AUTOSAR XML (schema 4-3-0)
package /MICROSAR/Dem_swc/DataTypes
  19 x impl type:
    Dem_EventIdType: range raw 1..65535, implementation-data-type=uint16
    Dem_RatioIdType: range raw 1..65535, implementation-data-type=uint16
    Dem_DTCStatusMaskType: range raw 0..255, implementation-data-type=uint8
    Dem_OperationCycleIdType: range raw 0..255, implementation-data-type=uint8
    Dem_DTCGroupType: range raw 0..16777215, implementation-data-type=uint32
    Dem_MaxDataValueType: category=ARRAY, sw-calibration-access=READ-ONLY
      element Dem_MaxDataValueTypeElement: array-size=1, array-size-semantics=FIXED-SIZE, implementation-data-type=uint8
    Dem_EventStatusType: compu {0=DEM_EVENT_STATUS_PASSED, 1=DEM_EVENT_STATUS_FAILED, 2=DEM_EVENT_STATUS_PREPASSED, 3=DEM_EVENT_STATUS_PREFAILED}, implementation-data-type=uint8
    Dem_EventStatusExtendedType: compu {1=DEM_UDS_STATUS_TF, 2=DEM_UDS_STATUS_TFTOC, 4=DEM_UDS_STATUS_PDTC, 8=DEM_UDS_STATUS_CDTC, 16=DEM_UDS_STATUS_TNCSLC, 32=DEM_UDS_STATUS_TFSLC, 64=DEM_UDS_STATUS_TNCTOC, 128=DEM_UDS_STATUS_WIR}, implementation-data-type=uint8
    Dem_UdsStatusByteType: compu {1=DEM_UDS_STATUS_TF, 2=DEM_UDS_STATUS_TFTOC, 4=DEM_UDS_STATUS_PDTC, 8=DEM_UDS_STATUS_CDTC, 16=DEM_UDS_STATUS_TNCSLC, 32=DEM_UDS_STATUS_TFSLC, 64=DEM_UDS_STATUS_TNCTOC, 128=DEM_UDS_STATUS_WIR}, implementation-data-type=uint8
    Dem_InitMonitorReasonType: compu {1=DEM_INIT_MONITOR_CLEAR, 2=DEM_INIT_MONITOR_RESTART, 3=DEM_INIT_MONITOR_REENABLED, 4=DEM_INIT_MONITOR_STORAGE_REENABLED}, implementation-data-type=uint8
    Dem_DTCOriginType: compu {1=DEM_DTC_ORIGIN_PRIMARY_MEMORY, 2=DEM_DTC_ORIGIN_MIRROR_MEMORY, 3=DEM_DTC_ORIGIN_PERMANENT_MEMORY, 4=DEM_DTC_ORIGIN_SECONDARY_MEMORY, 4=DEM_DTC_ORIGIN_USERDEFINED_MEMORY_10, 4=DEM_DTC_ORIGIN_USERDEFINED_MEMORY_11, 4=DEM_DTC_ORIGIN_USERDEFINED_MEMORY_12, 4=DEM_DTC_ORIGIN_USERDEFINED_MEMORY_13, 4=DEM_DTC_ORIGIN_USERDEFINED_MEMORY_14, 4=DEM_DTC_ORIGIN_USERDEFINED_MEMORY_15, 4=DEM_DTC_ORIGIN_USERDEFINED_MEMORY_16, 4=DEM_DTC_ORIGIN_USERDEFINED_MEMORY_17, 4=DEM_DTC_ORIGIN_USERDEFINED_MEMORY_18, 4=DEM_DTC_ORIGIN_USERDEFINED_MEMORY_19, 4=DEM_DTC_ORIGIN_USERDEFINED_MEMORY_1A, 4=DEM_DTC_ORIGIN_USERDEFINED_MEMORY_1B, 4=DEM_DTC_ORIGIN_USERDEFINED_MEMORY_1C, 4=DEM_DTC_ORIGIN_USERDEFINED_MEMORY_1D, 4=DEM_DTC_ORIGIN_USERDEFINED_MEMORY_1E, 4=DEM_DTC_ORIGIN_USERDEFINED_MEMORY_1F, 4=DEM_DTC_ORIGIN_USERDEFINED_MEMORY_20, 4=DEM_DTC_ORIGIN_USERDEFINED_MEMORY_21, 4=DEM_DTC_ORIGIN_USERDEFINED_MEMORY_22, 4=DEM_DTC_ORIGIN_USERDEFINED_MEMORY_23, 4=DEM_DTC_ORIGIN_USERDEFINED_MEMORY_24, 4=DEM_DTC_ORIGIN_USERDEFINED_MEMORY_25, 4=DEM_DTC_ORIGIN_USERDEFINED_MEMORY_26, 4=DEM_DTC_ORIGIN_USERDEFINED_MEMORY_27, 4=DEM_DTC_ORIGIN_USERDEFINED_MEMORY_28, 4=DEM_DTC_ORIGIN_USERDEFINED_MEMORY_29, 4=DEM_DTC_ORIGIN_USERDEFINED_MEMORY_2A, 4=DEM_DTC_ORIGIN_USERDEFINED_MEMORY_2B, 4=DEM_DTC_ORIGIN_USERDEFINED_MEMORY_2C, 4=DEM_DTC_ORIGIN_USERDEFINED_MEMORY_2D, 4=DEM_DTC_ORIGIN_USERDEFINED_MEMORY_2E, 4=DEM_DTC_ORIGIN_USERDEFINED_MEMORY_2F, 4=DEM_DTC_ORIGIN_USERDEFINED_MEMORY_30, 4=DEM_DTC_ORIGIN_USERDEFINED_MEMORY_31, 4=DEM_DTC_ORIGIN_USERDEFINED_MEMORY_32, 4=DEM_DTC_ORIGIN_USERDEFINED_MEMORY_33, 4=DEM_DTC_ORIGIN_USERDEFINED_MEMORY_34, 4=DEM_DTC_ORIGIN_USERDEFINED_MEMORY_35, 4=DEM_DTC_ORIGIN_USERDEFINED_MEMORY_36, 4=DEM_DTC_ORIGIN_USERDEFINED_MEMORY_37, 4=DEM_DTC_ORIGIN_USERDEFINED_MEMORY_38, 4=DEM_DTC_ORIGIN_USERDEFINED_MEMORY_39, 4=DEM_DTC_ORIGIN_USERDEFINED_MEMORY_3A, 4=DEM_DTC_ORIGIN_USERDEFINED_MEMORY_3B, 4=DEM_DTC_ORIGIN_USERDEFINED_MEMORY_3C, 4=DEM_DTC_ORIGIN_USERDEFINED_MEMORY_3D, 4=DEM_DTC_ORIGIN_USERDEFINED_MEMORY_3E, 4=DEM_DTC_ORIGIN_USERDEFINED_MEMORY_3F, 4=DEM_DTC_ORIGIN_USERDEFINED_MEMORY_40, 4=DEM_DTC_ORIGIN_USERDEFINED_MEMORY_41, 4=DEM_DTC_ORIGIN_USERDEFINED_MEMORY_42, 4=DEM_DTC_ORIGIN_USERDEFINED_MEMORY_43, 4=DEM_DTC_ORIGIN_USERDEFINED_MEMORY_44, 4=DEM_DTC_ORIGIN_USERDEFINED_MEMORY_45, 4=DEM_DTC_ORIGIN_USERDEFINED_MEMORY_46, 4=DEM_DTC_ORIGIN_USERDEFINED_MEMORY_47, 4=DEM_DTC_ORIGIN_USERDEFINED_MEMORY_48, 4=DEM_DTC_ORIGIN_USERDEFINED_MEMORY_49, 4=DEM_DTC_ORIGIN_USERDEFINED_MEMORY_4A, 4=DEM_DTC_ORIGIN_USERDEFINED_MEMORY_4B, 4=DEM_DTC_ORIGIN_USERDEFINED_MEMORY_4C, 4=DEM_DTC_ORIGIN_USERDEFINED_MEMORY_4D, 4=DEM_DTC_ORIGIN_USERDEFINED_MEMORY_4E, 4=DEM_DTC_ORIGIN_USERDEFINED_MEMORY_4F, 4=DEM_DTC_ORIGIN_USERDEFINED_MEMORY_50, 4=DEM_DTC_ORIGIN_USERDEFINED_MEMORY_51, 4=DEM_DTC_ORIGIN_USERDEFINED_MEMORY_52, 4=DEM_DTC_ORIGIN_USERDEFINED_MEMORY_53, 4=DEM_DTC_ORIGIN_USERDEFINED_MEMORY_54, 4=DEM_DTC_ORIGIN_USERDEFINED_MEMORY_55, 4=DEM_DTC_ORIGIN_USERDEFINED_MEMORY_56, 4=DEM_DTC_ORIGIN_USERDEFINED_MEMORY_57, 4=DEM_DTC_ORIGIN_USERDEFINED_MEMORY_58, 4=DEM_DTC_ORIGIN_USERDEFINED_MEMORY_59, 4=DEM_DTC_ORIGIN_USERDEFINED_MEMORY_5A, 4=DEM_DTC_ORIGIN_USERDEFINED_MEMORY_5B, 4=DEM_DTC_ORIGIN_USERDEFINED_MEMORY_5C, 4=DEM_DTC_ORIGIN_USERDEFINED_MEMORY_5D, 4=DEM_DTC_ORIGIN_USERDEFINED_MEMORY_5E, 4=DEM_DTC_ORIGIN_USERDEFINED_MEMORY_5F, 4=DEM_DTC_ORIGIN_USERDEFINED_MEMORY_60, 4=DEM_DTC_ORIGIN_USERDEFINED_MEMORY_61, 4=DEM_DTC_ORIGIN_USERDEFINED_MEMORY_62, 4=DEM_DTC_ORIGIN_USERDEFINED_MEMORY_63, 4=DEM_DTC_ORIGIN_USERDEFINED_MEMORY_64, 4=DEM_DTC_ORIGIN_USERDEFINED_MEMORY_65, 4=DEM_DTC_ORIGIN_USERDEFINED_MEMORY_66, 4=DEM_DTC_ORIGIN_USERDEFINED_MEMORY_67, 4=DEM_DTC_ORIGIN_USERDEFINED_MEMORY_68, 4=DEM_DTC_ORIGIN_USERDEFINED_MEMORY_69, 4=DEM_DTC_ORIGIN_USERDEFINED_MEMORY_6A, 4=DEM_DTC_ORIGIN_USERDEFINED_MEMORY_6B, 4=DEM_DTC_ORIGIN_USERDEFINED_MEMORY_6C, 4=DEM_DTC_ORIGIN_USERDEFINED_MEMORY_6D, 4=DEM_DTC_ORIGIN_USERDEFINED_MEMORY_6E, 4=DEM_DTC_ORIGIN_USERDEFINED_MEMORY_6F, 4=DEM_DTC_ORIGIN_USERDEFINED_MEMORY_70, 4=DEM_DTC_ORIGIN_USERDEFINED_MEMORY_71, 4=DEM_DTC_ORIGIN_USERDEFINED_MEMORY_72, 4=DEM_DTC_ORIGIN_USERDEFINED_MEMORY_73, 4=DEM_DTC_ORIGIN_USERDEFINED_MEMORY_74, 4=DEM_DTC_ORIGIN_USERDEFINED_MEMORY_75, 4=DEM_DTC_ORIGIN_USERDEFINED_MEMORY_76, 4=DEM_DTC_ORIGIN_USERDEFINED_MEMORY_77, 4=DEM_DTC_ORIGIN_USERDEFINED_MEMORY_78, 4=DEM_DTC_ORIGIN_USERDEFINED_MEMORY_79, 4=DEM_DTC_ORIGIN_USERDEFINED_MEMORY_7A, 4=DEM_DTC_ORIGIN_USERDEFINED_MEMORY_7B, 4=DEM_DTC_ORIGIN_USERDEFINED_MEMORY_7C, 4=DEM_DTC_ORIGIN_USERDEFINED_MEMORY_7D, 4=DEM_DTC_ORIGIN_USERDEFINED_MEMORY_7E, 4=DEM_DTC_ORIGIN_USERDEFINED_MEMORY_7F, 4=DEM_DTC_ORIGIN_USERDEFINED_MEMORY_80, 4=DEM_DTC_ORIGIN_USERDEFINED_MEMORY_81, 4=DEM_DTC_ORIGIN_USERDEFINED_MEMORY_82, 4=DEM_DTC_ORIGIN_USERDEFINED_MEMORY_83, 4=DEM_DTC_ORIGIN_USERDEFINED_MEMORY_84, 4=DEM_DTC_ORIGIN_USERDEFINED_MEMORY_85, 4=DEM_DTC_ORIGIN_USERDEFINED_MEMORY_86, 4=DEM_DTC_ORIGIN_USERDEFINED_MEMORY_87, 4=DEM_DTC_ORIGIN_USERDEFINED_MEMORY_88, 4=DEM_DTC_ORIGIN_USERDEFINED_MEMORY_89, 4=DEM_DTC_ORIGIN_USERDEFINED_MEMORY_8A, 4=DEM_DTC_ORIGIN_USERDEFINED_MEMORY_8B, 4=DEM_DTC_ORIGIN_USERDEFINED_MEMORY_8C, 4=DEM_DTC_ORIGIN_USERDEFINED_MEMORY_8D, 4=DEM_DTC_ORIGIN_USERDEFINED_MEMORY_8E, 4=DEM_DTC_ORIGIN_USERDEFINED_MEMORY_8F, 4=DEM_DTC_ORIGIN_USERDEFINED_MEMORY_90, 4=DEM_DTC_ORIGIN_USERDEFINED_MEMORY_91, 4=DEM_DTC_ORIGIN_USERDEFINED_MEMORY_92, 4=DEM_DTC_ORIGIN_USERDEFINED_MEMORY_93, 4=DEM_DTC_ORIGIN_USERDEFINED_MEMORY_94, 4=DEM_DTC_ORIGIN_USERDEFINED_MEMORY_95, 4=DEM_DTC_ORIGIN_USERDEFINED_MEMORY_96, 4=DEM_DTC_ORIGIN_USERDEFINED_MEMORY_97, 4=DEM_DTC_ORIGIN_USERDEFINED_MEMORY_98, 4=DEM_DTC_ORIGIN_USERDEFINED_MEMORY_99, 4=DEM_DTC_ORIGIN_USERDEFINED_MEMORY_9A, 4=DEM_DTC_ORIGIN_USERDEFINED_MEMORY_9B, 4=DEM_DTC_ORIGIN_USERDEFINED_MEMORY_9C, 4=DEM_DTC_ORIGIN_USERDEFINED_MEMORY_9D, 4=DEM_DTC_ORIGIN_USERDEFINED_MEMORY_9E, 4=DEM_DTC_ORIGIN_USERDEFINED_MEMORY_9F, 4=DEM_DTC_ORIGIN_USERDEFINED_MEMORY_A0, 4=DEM_DTC_ORIGIN_USERDEFINED_MEMORY_A1, 4=DEM_DTC_ORIGIN_USERDEFINED_MEMORY_A2, 4=DEM_DTC_ORIGIN_USERDEFINED_MEMORY_A3, 4=DEM_DTC_ORIGIN_USERDEFINED_MEMORY_A4, 4=DEM_DTC_ORIGIN_USERDEFINED_MEMORY_A5, 4=DEM_DTC_ORIGIN_USERDEFINED_MEMORY_A6, 4=DEM_DTC_ORIGIN_USERDEFINED_MEMORY_A7, 4=DEM_DTC_ORIGIN_USERDEFINED_MEMORY_A8, 4=DEM_DTC_ORIGIN_USERDEFINED_MEMORY_A9, 4=DEM_DTC_ORIGIN_USERDEFINED_MEMORY_AA, 4=DEM_DTC_ORIGIN_USERDEFINED_MEMORY_AB, 4=DEM_DTC_ORIGIN_USERDEFINED_MEMORY_AC, 4=DEM_DTC_ORIGIN_USERDEFINED_MEMORY_AD, 4=DEM_DTC_ORIGIN_USERDEFINED_MEMORY_AE, 4=DEM_DTC_ORIGIN_USERDEFINED_MEMORY_AF, 4=DEM_DTC_ORIGIN_USERDEFINED_MEMORY_B0, 4=DEM_DTC_ORIGIN_USERDEFINED_MEMORY_B1, 4=DEM_DTC_ORIGIN_USERDEFINED_MEMORY_B2, 4=DEM_DTC_ORIGIN_USERDEFINED_MEMORY_B3, 4=DEM_DTC_ORIGIN_USERDEFINED_MEMORY_B4, 4=DEM_DTC_ORIGIN_USERDEFINED_MEMORY_B5, 4=DEM_DTC_ORIGIN_USERDEFINED_MEMORY_B6, 4=DEM_DTC_ORIGIN_USERDEFINED_MEMORY_B7, 4=DEM_DTC_ORIGIN_USERDEFINED_MEMORY_B8, 4=DEM_DTC_ORIGIN_USERDEFINED_MEMORY_B9, 4=DEM_DTC_ORIGIN_USERDEFINED_MEMORY_BA, 4=DEM_DTC_ORIGIN_USERDEFINED_MEMORY_BB, 4=DEM_DTC_ORIGIN_USERDEFINED_MEMORY_BC, 4=DEM_DTC_ORIGIN_USERDEFINED_MEMORY_BD, 4=DEM_DTC_ORIGIN_USERDEFINED_MEMORY_BE, 4=DEM_DTC_ORIGIN_USERDEFINED_MEMORY_BF, 4=DEM_DTC_ORIGIN_USERDEFINED_MEMORY_C0, 4=DEM_DTC_ORIGIN_USERDEFINED_MEMORY_C1, 4=DEM_DTC_ORIGIN_USERDEFINED_MEMORY_C2, 4=DEM_DTC_ORIGIN_USERDEFINED_MEMORY_C3, 4=DEM_DTC_ORIGIN_USERDEFINED_MEMORY_C4, 4=DEM_DTC_ORIGIN_USERDEFINED_MEMORY_C5, 4=DEM_DTC_ORIGIN_USERDEFINED_MEMORY_C6, 4=DEM_DTC_ORIGIN_USERDEFINED_MEMORY_C7, 4=DEM_DTC_ORIGIN_USERDEFINED_MEMORY_C8, 4=DEM_DTC_ORIGIN_USERDEFINED_MEMORY_C9, 4=DEM_DTC_ORIGIN_USERDEFINED_MEMORY_CA, 4=DEM_DTC_ORIGIN_USERDEFINED_MEMORY_CB, 4=DEM_DTC_ORIGIN_USERDEFINED_MEMORY_CC, 4=DEM_DTC_ORIGIN_USERDEFINED_MEMORY_CD, 4=DEM_DTC_ORIGIN_USERDEFINED_MEMORY_CE, 4=DEM_DTC_ORIGIN_USERDEFINED_MEMORY_CF, 4=DEM_DTC_ORIGIN_USERDEFINED_MEMORY_D0, 4=DEM_DTC_ORIGIN_USERDEFINED_MEMORY_D1, 4=DEM_DTC_ORIGIN_USERDEFINED_MEMORY_D2, 4=DEM_DTC_ORIGIN_USERDEFINED_MEMORY_D3, 4=DEM_DTC_ORIGIN_USERDEFINED_MEMORY_D4, 4=DEM_DTC_ORIGIN_USERDEFINED_MEMORY_D5, 4=DEM_DTC_ORIGIN_USERDEFINED_MEMORY_D6, 4=DEM_DTC_ORIGIN_USERDEFINED_MEMORY_D7, 4=DEM_DTC_ORIGIN_USERDEFINED_MEMORY_D8, 4=DEM_DTC_ORIGIN_USERDEFINED_MEMORY_D9, 4=DEM_DTC_ORIGIN_USERDEFINED_MEMORY_DA, 4=DEM_DTC_ORIGIN_USERDEFINED_MEMORY_DB, 4=DEM_DTC_ORIGIN_USERDEFINED_MEMORY_DC, 4=DEM_DTC_ORIGIN_USERDEFINED_MEMORY_DD, 4=DEM_DTC_ORIGIN_USERDEFINED_MEMORY_DE, 4=DEM_DTC_ORIGIN_USERDEFINED_MEMORY_DF, 4=DEM_DTC_ORIGIN_USERDEFINED_MEMORY_E0, 4=DEM_DTC_ORIGIN_USERDEFINED_MEMORY_E1, 4=DEM_DTC_ORIGIN_USERDEFINED_MEMORY_E2, 4=DEM_DTC_ORIGIN_USERDEFINED_MEMORY_E3, 4=DEM_DTC_ORIGIN_USERDEFINED_MEMORY_E4, 4=DEM_DTC_ORIGIN_USERDEFINED_MEMORY_E5, 4=DEM_DTC_ORIGIN_USERDEFINED_MEMORY_E6, 4=DEM_DTC_ORIGIN_USERDEFINED_MEMORY_E7, 4=DEM_DTC_ORIGIN_USERDEFINED_MEMORY_E8, 4=DEM_DTC_ORIGIN_USERDEFINED_MEMORY_E9, 4=DEM_DTC_ORIGIN_USERDEFINED_MEMORY_EA, 4=DEM_DTC_ORIGIN_USERDEFINED_MEMORY_EB, 4=DEM_DTC_ORIGIN_USERDEFINED_MEMORY_EC, 4=DEM_DTC_ORIGIN_USERDEFINED_MEMORY_ED, 4=DEM_DTC_ORIGIN_USERDEFINED_MEMORY_EE, 4=DEM_DTC_ORIGIN_USERDEFINED_MEMORY_EF, 4=DEM_DTC_ORIGIN_USERDEFINED_MEMORY_F0, 4=DEM_DTC_ORIGIN_USERDEFINED_MEMORY_F1, 4=DEM_DTC_ORIGIN_USERDEFINED_MEMORY_F2, 4=DEM_DTC_ORIGIN_USERDEFINED_MEMORY_F3, 4=DEM_DTC_ORIGIN_USERDEFINED_MEMORY_F4, 4=DEM_DTC_ORIGIN_USERDEFINED_MEMORY_F5, 4=DEM_DTC_ORIGIN_USERDEFINED_MEMORY_F6, 4=DEM_DTC_ORIGIN_USERDEFINED_MEMORY_F7, 4=DEM_DTC_ORIGIN_USERDEFINED_MEMORY_F8, 4=DEM_DTC_ORIGIN_USERDEFINED_MEMORY_F9, 4=DEM_DTC_ORIGIN_USERDEFINED_MEMORY_FA, 4=DEM_DTC_ORIGIN_USERDEFINED_MEMORY_FB, 4=DEM_DTC_ORIGIN_USERDEFINED_MEMORY_FC, 4=DEM_DTC_ORIGIN_USERDEFINED_MEMORY_FD, 4=DEM_DTC_ORIGIN_USERDEFINED_MEMORY_FE, 4=DEM_DTC_ORIGIN_USERDEFINED_MEMORY_FF}, implementation-data-type=uint8
    Dem_DTCFormatType: compu {0=DEM_DTC_FORMAT_OBD, 1=DEM_DTC_FORMAT_UDS, 2=DEM_DTC_FORMAT_J1939}, implementation-data-type=uint8
    Dem_OperationCycleStateType: compu {0=DEM_CYCLE_STATE_START, 1=DEM_CYCLE_STATE_END}, implementation-data-type=uint8
    Dem_IndicatorStatusType: compu {0=DEM_INDICATOR_OFF, 1=DEM_INDICATOR_CONTINUOUS, 2=DEM_INDICATOR_BLINKING, 3=DEM_INDICATOR_BLINK_CONT, 4=DEM_INDICATOR_SLOW_FLASH, 5=DEM_INDICATOR_FAST_FLASH, 6=DEM_INDICATOR_ON_DEMAND, 7=DEM_INDICATOR_SHORT}, implementation-data-type=uint8
    Dem_DTCKindType: compu {1=DEM_DTC_KIND_ALL_DTCS, 2=DEM_DTC_KIND_EMISSION_REL_DTCS}, implementation-data-type=uint8
    Dem_IumprDenomCondIdType: compu {1=DEM_IUMPR_GENERAL_DENOMINATOR, 2=DEM_IUMPR_DEN_COND_COLDSTART, 3=DEM_IUMPR_DEN_COND_EVAP, 4=DEM_IUMPR_DEN_COND_500MI}, implementation-data-type=uint8
    Dem_IumprDenomCondStatusType: compu {0=DEM_IUMPR_DEN_STATUS_NOT_REACHED, 1=DEM_IUMPR_DEN_STATUS_REACHED, 2=DEM_IUMPR_DEN_STATUS_INHIBITED}, implementation-data-type=uint8
    Dem_DebounceResetStatusType: compu {0=DEM_DEBOUNCE_STATUS_FREEZE, 1=DEM_DEBOUNCE_STATUS_RESET}, implementation-data-type=uint8
    Dem_DebouncingStateType: compu {1=DEM_TEMPORARILY_DEFECTIVE, 2=DEM_FINALLY_DEFECTIVE, 4=DEM_TEMPORARILY_HEALED, 8=DEM_TEST_COMPLETE, 16=DEM_DTR_UPDATE}, implementation-data-type=uint8
package /MICROSAR/Dem_swc/Interfaces
  7 x client server interface, all with is-service=true, service-kind=DIAGNOSTIC-EVENT-MANAGER:
    CddIf
      operation ClearDTC: possible-error=[CddIf/DEM_CLEAR_WRONG_DTC, CddIf/DEM_CLEAR_WRONG_DTCORIGIN, CddIf/DEM_CLEAR_FAILED, CddIf/DEM_CLEAR_PENDING, CddIf/DEM_CLEAR_BUSY, CddIf/DEM_CLEAR_MEMORY_ERROR]
        arg DTC: type=uint32, direction=IN
        arg DTCFormat: type=Dem_DTCFormatType, direction=IN
        arg DTCOrigin: type=Dem_DTCOriginType, direction=IN
      6 x error:
        DEM_CLEAR_WRONG_DTC: error-code=1
        DEM_CLEAR_WRONG_DTCORIGIN: error-code=2
        DEM_CLEAR_FAILED: error-code=3
        DEM_CLEAR_PENDING: error-code=4
        DEM_CLEAR_BUSY: error-code=5
        DEM_CLEAR_MEMORY_ERROR: error-code=6
    DemServices
      operation GetPostRunRequested: possible-error=DemServices/E_NOT_OK
        arg IsRequested: type=boolean, direction=OUT
      operation GetDTCStatusAvailabilityMask: possible-error=DemServices/E_NOT_OK
        arg DTCStatusMask: type=uint8, direction=OUT
      error E_NOT_OK: error-code=1
    EvMemOverflowIndication
      operation GetEventMemoryOverflow: possible-error=EvMemOverflowIndication/E_NOT_OK
        arg OverflowIndication: type=boolean, direction=OUT
      operation GetNumberOfEventMemoryEntries: possible-error=EvMemOverflowIndication/E_NOT_OK
        arg NumberOfEventMemoryEntries: type=uint8, direction=OUT
      error E_NOT_OK: error-code=1
    GeneralDiagnosticInfo
      9 x operation:
        GetEventStatus: possible-error=GeneralDiagnosticInfo/E_NOT_OK
          arg EventId: type=Dem_EventIdType, direction=IN
          arg EventStatusExtended: type=Dem_EventStatusExtendedType, direction=OUT
        GetEventFailed: possible-error=GeneralDiagnosticInfo/E_NOT_OK
          arg EventId: type=Dem_EventIdType, direction=IN
          arg EventFailed: type=boolean, direction=OUT
        GetEventTested: possible-error=GeneralDiagnosticInfo/E_NOT_OK
          arg EventId: type=Dem_EventIdType, direction=IN
          arg EventTested: type=boolean, direction=OUT
        GetDTCOfEvent: possible-error=[GeneralDiagnosticInfo/E_NOT_OK, GeneralDiagnosticInfo/DEM_E_NO_DTC_AVAILABLE]
          arg EventId: type=Dem_EventIdType, direction=IN
          arg DTCFormat: type=Dem_DTCFormatType, direction=IN
          arg DTCOfEvent: type=uint32, direction=OUT
        GetFaultDetectionCounter: possible-error=[GeneralDiagnosticInfo/E_NOT_OK, GeneralDiagnosticInfo/DEM_E_NO_FDC_AVAILABLE]
          arg EventId: type=Dem_EventIdType, direction=IN
          arg FaultDetectionCounter: type=sint8, direction=OUT
        GetEventFreezeFrameData: possible-error=[GeneralDiagnosticInfo/E_NOT_OK, GeneralDiagnosticInfo/DEM_E_NODATAAVAILABLE, GeneralDiagnosticInfo/DEM_E_WRONG_RECORDNUMBER, GeneralDiagnosticInfo/DEM_E_WRONG_DIDNUMBER]
          5 x arg:
            EventId: type=Dem_EventIdType, direction=IN
            RecordNumber: type=uint8, direction=IN
            ReportTotalRecord: type=boolean, direction=IN
            DataId: type=uint16, direction=IN
            DestBuffer: type=Dem_MaxDataValueType, direction=OUT
        GetEventExtendedDataRecord: possible-error=[GeneralDiagnosticInfo/E_NOT_OK, GeneralDiagnosticInfo/DEM_E_NODATAAVAILABLE, GeneralDiagnosticInfo/DEM_E_WRONG_RECORDNUMBER]
          arg EventId: type=Dem_EventIdType, direction=IN
          arg RecordNumber: type=uint8, direction=IN
          arg DestBuffer: type=Dem_MaxDataValueType, direction=OUT
        GetEventEnableCondition: possible-error=GeneralDiagnosticInfo/E_NOT_OK
          arg EventId: type=Dem_EventIdType, direction=IN
          arg ConditionFullfilled: type=boolean, direction=OUT
        GetDebouncingOfEvent: possible-error=GeneralDiagnosticInfo/E_NOT_OK
          arg EventId: type=Dem_EventIdType, direction=IN
          arg DebouncingState: type=Dem_DebouncingStateType, direction=OUT
      6 x error:
        E_NOT_OK: error-code=1
        DEM_E_NO_DTC_AVAILABLE: error-code=2
        DEM_E_NO_FDC_AVAILABLE: error-code=3
        DEM_E_NODATAAVAILABLE: error-code=48
        DEM_E_WRONG_RECORDNUMBER: error-code=49
        DEM_E_WRONG_DIDNUMBER: error-code=50
    DiagnosticInfo
      9 x operation:
        GetEventStatus: possible-error=DiagnosticInfo/E_NOT_OK
          arg EventStatusExtended: type=Dem_EventStatusExtendedType, direction=OUT
        GetEventFailed: possible-error=DiagnosticInfo/E_NOT_OK
          arg EventFailed: type=boolean, direction=OUT
        GetEventTested: possible-error=DiagnosticInfo/E_NOT_OK
          arg EventTested: type=boolean, direction=OUT
        GetDTCOfEvent: possible-error=[DiagnosticInfo/E_NOT_OK, DiagnosticInfo/DEM_E_NO_DTC_AVAILABLE]
          arg DTCFormat: type=Dem_DTCFormatType, direction=IN
          arg DTCOfEvent: type=uint32, direction=OUT
        GetFaultDetectionCounter: possible-error=[DiagnosticInfo/E_NOT_OK, DiagnosticInfo/DEM_E_NO_FDC_AVAILABLE]
          arg FaultDetectionCounter: type=sint8, direction=OUT
        GetEventFreezeFrameData: possible-error=[DiagnosticInfo/E_NOT_OK, DiagnosticInfo/DEM_E_NODATAAVAILABLE, DiagnosticInfo/DEM_E_WRONG_RECORDNUMBER, DiagnosticInfo/DEM_E_WRONG_DIDNUMBER]
          4 x arg:
            RecordNumber: type=uint8, direction=IN
            ReportTotalRecord: type=boolean, direction=IN
            DataId: type=uint16, direction=IN
            DestBuffer: type=Dem_MaxDataValueType, direction=OUT
        GetEventExtendedDataRecord: possible-error=[DiagnosticInfo/E_NOT_OK, DiagnosticInfo/DEM_E_NODATAAVAILABLE, DiagnosticInfo/DEM_E_WRONG_RECORDNUMBER]
          arg RecordNumber: type=uint8, direction=IN
          arg DestBuffer: type=Dem_MaxDataValueType, direction=OUT
        GetEventEnableCondition: possible-error=DiagnosticInfo/E_NOT_OK
          arg ConditionFullfilled: type=boolean, direction=OUT
        GetDebouncingOfEvent: possible-error=DiagnosticInfo/E_NOT_OK
          arg DebouncingState: type=Dem_DebouncingStateType, direction=OUT
      6 x error:
        E_NOT_OK: error-code=1
        DEM_E_NO_DTC_AVAILABLE: error-code=2
        DEM_E_NO_FDC_AVAILABLE: error-code=3
        DEM_E_NODATAAVAILABLE: error-code=48
        DEM_E_WRONG_RECORDNUMBER: error-code=49
        DEM_E_WRONG_DIDNUMBER: error-code=50
    DcmIf
      5 x operation:
        DcmClearDTC: possible-error=[DcmIf/DEM_CLEAR_WRONG_DTC, DcmIf/DEM_CLEAR_WRONG_DTCORIGIN, DcmIf/DEM_CLEAR_FAILED, DcmIf/DEM_CLEAR_PENDING, DcmIf/DEM_CLEAR_BUSY, DcmIf/DEM_CLEAR_MEMORY_ERROR]
          arg DTC: type=uint32, direction=IN
          arg DTCFormat: type=Dem_DTCFormatType, direction=IN
          arg DTCOrigin: type=Dem_DTCOriginType, direction=IN
        DcmGetNextFilteredDTCAndFDC: possible-error=DEM_FILTERED_NO_MATCHING_DTC
          arg DTC: type=uint32, direction=OUT
          arg DTCFaultDetectionCounter: type=sint8, direction=OUT
        DcmEnableDTCSetting: possible-error=[DEM_CONTROL_DTC_SETTING_N_OK, DEM_CONTROL_DTC_WRONG_DTCGROUP]
          arg DTCGroup: type=Dem_DTCGroupType, direction=IN
          arg DTCKind: type=Dem_DTCKindType, direction=IN
        DcmGetFreezeFrameDataByDTC: possible-error=[DEM_GET_FFDATABYDTC_WRONG_DTC, DEM_GET_FFDATABYDTC_WRONG_DTCORIGIN, DEM_GET_FFDATABYDTC_WRONG_RECORDNUMBER, DEM_GET_FFDATABYDTC_WRONG_BUFFERSIZE, DEM_GET_FFDATABYDTC_PENDING]
          5 x arg:
            DTC: type=uint32, direction=IN
            DTCOrigin: type=Dem_DTCOriginType, direction=IN
            RecordNumber: type=uint8, direction=IN
            DestBuffer: type=uint8, direction=OUT
            BufSize: type=uint16, direction=INOUT
        DcmGetExtendedDataRecordByDTC: possible-error=[DEM_RECORD_WRONG_DTC, DEM_RECORD_WRONG_DTCORIGIN, DEM_RECORD_WRONG_NUMBER, DEM_RECORD_WRONG_BUFFERSIZE, DEM_RECORD_PENDING]
          5 x arg:
            DTC: type=uint32, direction=IN
            DTCOrigin: type=Dem_DTCOriginType, direction=IN
            ExtendedDataNumber: type=uint8, direction=IN
            DestBuffer: type=uint8, direction=OUT
            BufSize: type=uint16, direction=INOUT
      19 x error:
        DEM_CLEAR_WRONG_DTC: error-code=1
        DEM_CONTROL_DTC_SETTING_N_OK: error-code=1
        DEM_FILTERED_NO_MATCHING_DTC: error-code=1
        DEM_GET_FFDATABYDTC_WRONG_DTC: error-code=1
        DEM_RECORD_WRONG_DTC: error-code=1
        DEM_CLEAR_WRONG_DTCORIGIN: error-code=2
        DEM_CONTROL_DTC_WRONG_DTCGROUP: error-code=2
        DEM_GET_FFDATABYDTC_WRONG_DTCORIGIN: error-code=2
        DEM_RECORD_WRONG_DTCORIGIN: error-code=2
        DEM_CLEAR_FAILED: error-code=3
        DEM_GET_FFDATABYDTC_WRONG_RECORDNUMBER: error-code=3
        DEM_RECORD_WRONG_NUMBER: error-code=3
        DEM_CLEAR_PENDING: error-code=4
        DEM_GET_FFDATABYDTC_WRONG_BUFFERSIZE: error-code=4
        DEM_RECORD_WRONG_BUFFERSIZE: error-code=4
        DEM_CLEAR_BUSY: error-code=5
        DEM_GET_FFDATABYDTC_PENDING: error-code=5
        DEM_RECORD_PENDING: error-code=5
        DEM_CLEAR_MEMORY_ERROR: error-code=6
    OperationCycle
      operation SetOperationCycleState: possible-error=OperationCycle/E_NOT_OK
        arg CycleState: type=Dem_OperationCycleStateType, direction=IN
      error E_NOT_OK: error-code=1
package /MICROSAR/Dem_swc/ComponentTypes
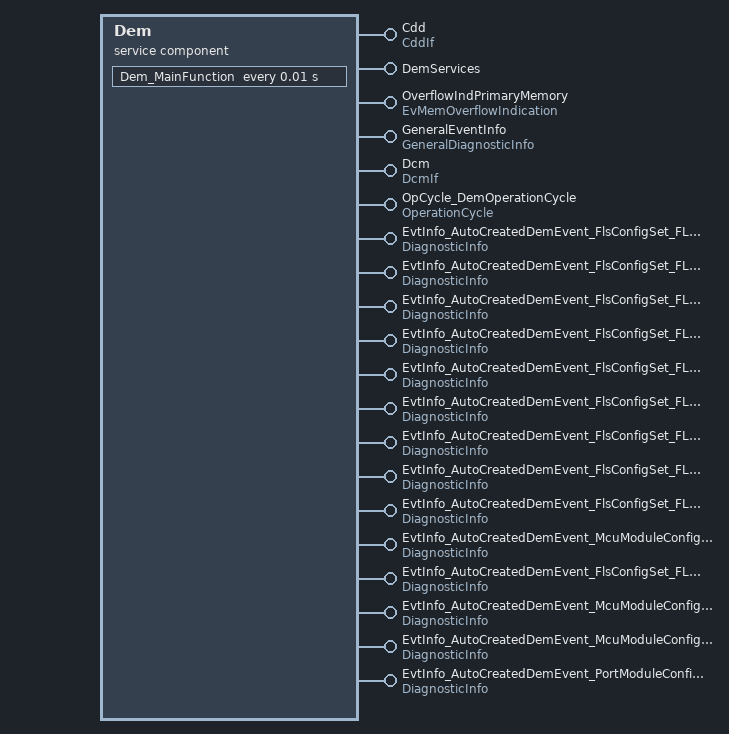
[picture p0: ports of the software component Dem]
  service sw component type Dem: category=SERVICE_COMPONENT
    20 x provide port:
      Cdd: provided-interface=CddIf
      DemServices: provided-interface=DemServices
      OverflowIndPrimaryMemory: provided-interface=EvMemOverflowIndication
      GeneralEventInfo: provided-interface=GeneralDiagnosticInfo
      Dcm: provided-interface=DcmIf
      OpCycle_DemOperationCycle: provided-interface=OperationCycle
      EvtInfo_AutoCreatedDemEvent_FlsConfigSet_FLS_E_COMPARE_FAILED: provided-interface=DiagnosticInfo
      EvtInfo_AutoCreatedDemEvent_FlsConfigSet_FLS_E_UNEXPECTED_FLASH_ID: provided-interface=DiagnosticInfo
      EvtInfo_AutoCreatedDemEvent_FlsConfigSet_FLS_E_WRITE_FAILED: provided-interface=DiagnosticInfo
      EvtInfo_AutoCreatedDemEvent_FlsConfigSet_FLS_E_READ_FAILED: provided-interface=DiagnosticInfo
      EvtInfo_AutoCreatedDemEvent_FlsConfigSet_FLS_E_ERASE_FAILED: provided-interface=DiagnosticInfo
      EvtInfo_AutoCreatedDemEvent_FlsConfigSet_FLS_E_HW_FAILURE: provided-interface=DiagnosticInfo
      EvtInfo_AutoCreatedDemEvent_FlsConfigSet_FLS_E_INT_INCONSISTENT: provided-interface=DiagnosticInfo
      EvtInfo_AutoCreatedDemEvent_FlsConfigSet_FLS_E_READ_FAILED_DED: provided-interface=DiagnosticInfo
      EvtInfo_AutoCreatedDemEvent_FlsConfigSet_FLS_E_REG_WRITE_VERIFY: provided-interface=DiagnosticInfo
      EvtInfo_AutoCreatedDemEvent_McuModuleConfiguration_MCU_E_CLOCK_FAILURE: provided-interface=DiagnosticInfo
      EvtInfo_AutoCreatedDemEvent_FlsConfigSet_FLS_E_ECC_FAILED: provided-interface=DiagnosticInfo
      EvtInfo_AutoCreatedDemEvent_McuModuleConfiguration_MCU_E_RESETCONTROLLER_STARTUP_FAILURE: provided-interface=DiagnosticInfo
      EvtInfo_AutoCreatedDemEvent_McuModuleConfiguration_MCU_E_WRITE_TIMEOUT_FAILURE: provided-interface=DiagnosticInfo
      EvtInfo_AutoCreatedDemEvent_PortModuleConfiguration_PORT_E_WRITE_TIMEOUT_FAILURE: provided-interface=DiagnosticInfo
    behavior DemInternalBehavior: handle-termination-and-restart=NO-SUPPORT, included-data-type-set=data-type=[Dem_EventIdType, Dem_RatioIdType, Dem_EventStatusType, Dem_EventStatusExtendedType, Dem_UdsStatusByteType, Dem_DTCFormatType, Dem_InitMonitorReasonType, Dem_OperationCycleStateType, Dem_DTCStatusMaskType, Dem_IndicatorStatusType, Dem_MaxDataValueType, Dem_DTCKindType, Dem_DTCGroupType, Dem_IumprDenomCondIdType, Dem_IumprDenomCondStatusType, Dem_DebounceResetStatusType, Dem_DebouncingStateType]
      timing event Timer_Dem_MainFunction: start-on-event=Dem_MainFunction, period=0.01
      146 x operation invoked event:
        OpEventClearDTC_ClearDTC_Cdd: start-on-event=ClearDTC, operation=Cdd.ClearDTC
        OpEventPostRunRequested_GetPostRunRequested_DemServices: start-on-event=PostRunRequested, operation=DemServices.GetPostRunRequested
        OpEventGetDTCStatusAvailabilityMask_GetDTCStatusAvailabilityMask_DemServices: start-on-event=GetDTCStatusAvailabilityMask, operation=DemServices.GetDTCStatusAvailabilityMask
        OpEventGetEventMemoryOverflow_GetEventMemoryOverflow_OverflowIndPrimaryMemory: start-on-event=GetEventMemoryOverflow, operation=OverflowIndPrimaryMemory.GetEventMemoryOverflow
        OpEventGetNumberOfEventMemoryEntries_GetNumberOfEventMemoryEntries_OverflowIndPrimaryMemory: start-on-event=GetNumberOfEventMemoryEntries, operation=OverflowIndPrimaryMemory.GetNumberOfEventMemoryEntries
        OpEventGetEventStatus_GetEventStatus_GeneralEventInfo: start-on-event=GetEventStatus, operation=GeneralEventInfo.GetEventStatus
        OpEventGetEventStatus_GetEventStatus_EvtInfo_AutoCreatedDemEvent_FlsConfigSet_FLS_E_COMPARE_FAILED: start-on-event=GetEventStatus, operation=EvtInfo_AutoCreatedDemEvent_FlsConfigSet_FLS_E_COMPARE_FAILED.GetEventStatus
        OpEventGetEventStatus_GetEventStatus_EvtInfo_AutoCreatedDemEvent_FlsConfigSet_FLS_E_UNEXPECTED_FLASH_ID: start-on-event=GetEventStatus, operation=EvtInfo_AutoCreatedDemEvent_FlsConfigSet_FLS_E_UNEXPECTED_FLASH_ID.GetEventStatus
        OpEventGetEventStatus_GetEventStatus_EvtInfo_AutoCreatedDemEvent_FlsConfigSet_FLS_E_WRITE_FAILED: start-on-event=GetEventStatus, operation=EvtInfo_AutoCreatedDemEvent_FlsConfigSet_FLS_E_WRITE_FAILED.GetEventStatus
        OpEventGetEventStatus_GetEventStatus_EvtInfo_AutoCreatedDemEvent_FlsConfigSet_FLS_E_READ_FAILED: start-on-event=GetEventStatus, operation=EvtInfo_AutoCreatedDemEvent_FlsConfigSet_FLS_E_READ_FAILED.GetEventStatus
        OpEventGetEventStatus_GetEventStatus_EvtInfo_AutoCreatedDemEvent_FlsConfigSet_FLS_E_ERASE_FAILED: start-on-event=GetEventStatus, operation=EvtInfo_AutoCreatedDemEvent_FlsConfigSet_FLS_E_ERASE_FAILED.GetEventStatus
        OpEventGetEventStatus_GetEventStatus_EvtInfo_AutoCreatedDemEvent_FlsConfigSet_FLS_E_HW_FAILURE: start-on-event=GetEventStatus, operation=EvtInfo_AutoCreatedDemEvent_FlsConfigSet_FLS_E_HW_FAILURE.GetEventStatus
        OpEventGetEventStatus_GetEventStatus_EvtInfo_AutoCreatedDemEvent_FlsConfigSet_FLS_E_INT_INCONSISTENT: start-on-event=GetEventStatus, operation=EvtInfo_AutoCreatedDemEvent_FlsConfigSet_FLS_E_INT_INCONSISTENT.GetEventStatus
        OpEventGetEventStatus_GetEventStatus_EvtInfo_AutoCreatedDemEvent_FlsConfigSet_FLS_E_READ_FAILED_DED: start-on-event=GetEventStatus, operation=EvtInfo_AutoCreatedDemEvent_FlsConfigSet_FLS_E_READ_FAILED_DED.GetEventStatus
        OpEventGetEventStatus_GetEventStatus_EvtInfo_AutoCreatedDemEvent_FlsConfigSet_FLS_E_REG_WRITE_VERIFY: start-on-event=GetEventStatus, operation=EvtInfo_AutoCreatedDemEvent_FlsConfigSet_FLS_E_REG_WRITE_VERIFY.GetEventStatus
        OpEventGetEventFailed_GetEventFailed_GeneralEventInfo: start-on-event=GetEventFailed, operation=GeneralEventInfo.GetEventFailed
        OpEventGetEventFailed_GetEventFailed_EvtInfo_AutoCreatedDemEvent_FlsConfigSet_FLS_E_COMPARE_FAILED: start-on-event=GetEventFailed, operation=EvtInfo_AutoCreatedDemEvent_FlsConfigSet_FLS_E_COMPARE_FAILED.GetEventFailed
        OpEventGetEventFailed_GetEventFailed_EvtInfo_AutoCreatedDemEvent_FlsConfigSet_FLS_E_UNEXPECTED_FLASH_ID: start-on-event=GetEventFailed, operation=EvtInfo_AutoCreatedDemEvent_FlsConfigSet_FLS_E_UNEXPECTED_FLASH_ID.GetEventFailed
        OpEventGetEventFailed_GetEventFailed_EvtInfo_AutoCreatedDemEvent_FlsConfigSet_FLS_E_WRITE_FAILED: start-on-event=GetEventFailed, operation=EvtInfo_AutoCreatedDemEvent_FlsConfigSet_FLS_E_WRITE_FAILED.GetEventFailed
        OpEventGetEventFailed_GetEventFailed_EvtInfo_AutoCreatedDemEvent_FlsConfigSet_FLS_E_READ_FAILED: start-on-event=GetEventFailed, operation=EvtInfo_AutoCreatedDemEvent_FlsConfigSet_FLS_E_READ_FAILED.GetEventFailed
        OpEventGetEventFailed_GetEventFailed_EvtInfo_AutoCreatedDemEvent_FlsConfigSet_FLS_E_ERASE_FAILED: start-on-event=GetEventFailed, operation=EvtInfo_AutoCreatedDemEvent_FlsConfigSet_FLS_E_ERASE_FAILED.GetEventFailed
        OpEventGetEventFailed_GetEventFailed_EvtInfo_AutoCreatedDemEvent_FlsConfigSet_FLS_E_HW_FAILURE: start-on-event=GetEventFailed, operation=EvtInfo_AutoCreatedDemEvent_FlsConfigSet_FLS_E_HW_FAILURE.GetEventFailed
        OpEventGetEventFailed_GetEventFailed_EvtInfo_AutoCreatedDemEvent_FlsConfigSet_FLS_E_INT_INCONSISTENT: start-on-event=GetEventFailed, operation=EvtInfo_AutoCreatedDemEvent_FlsConfigSet_FLS_E_INT_INCONSISTENT.GetEventFailed
        OpEventGetEventFailed_GetEventFailed_EvtInfo_AutoCreatedDemEvent_FlsConfigSet_FLS_E_READ_FAILED_DED: start-on-event=GetEventFailed, operation=EvtInfo_AutoCreatedDemEvent_FlsConfigSet_FLS_E_READ_FAILED_DED.GetEventFailed
        OpEventGetEventFailed_GetEventFailed_EvtInfo_AutoCreatedDemEvent_FlsConfigSet_FLS_E_REG_WRITE_VERIFY: start-on-event=GetEventFailed, operation=EvtInfo_AutoCreatedDemEvent_FlsConfigSet_FLS_E_REG_WRITE_VERIFY.GetEventFailed
        OpEventGetEventTested_GetEventTested_GeneralEventInfo: start-on-event=GetEventTested, operation=GeneralEventInfo.GetEventTested
        OpEventGetEventTested_GetEventTested_EvtInfo_AutoCreatedDemEvent_FlsConfigSet_FLS_E_COMPARE_FAILED: start-on-event=GetEventTested, operation=EvtInfo_AutoCreatedDemEvent_FlsConfigSet_FLS_E_COMPARE_FAILED.GetEventTested
        OpEventGetEventTested_GetEventTested_EvtInfo_AutoCreatedDemEvent_FlsConfigSet_FLS_E_UNEXPECTED_FLASH_ID: start-on-event=GetEventTested, operation=EvtInfo_AutoCreatedDemEvent_FlsConfigSet_FLS_E_UNEXPECTED_FLASH_ID.GetEventTested
        OpEventGetEventTested_GetEventTested_EvtInfo_AutoCreatedDemEvent_FlsConfigSet_FLS_E_WRITE_FAILED: start-on-event=GetEventTested, operation=EvtInfo_AutoCreatedDemEvent_FlsConfigSet_FLS_E_WRITE_FAILED.GetEventTested
        OpEventGetEventTested_GetEventTested_EvtInfo_AutoCreatedDemEvent_FlsConfigSet_FLS_E_READ_FAILED: start-on-event=GetEventTested, operation=EvtInfo_AutoCreatedDemEvent_FlsConfigSet_FLS_E_READ_FAILED.GetEventTested
        OpEventGetEventTested_GetEventTested_EvtInfo_AutoCreatedDemEvent_FlsConfigSet_FLS_E_ERASE_FAILED: start-on-event=GetEventTested, operation=EvtInfo_AutoCreatedDemEvent_FlsConfigSet_FLS_E_ERASE_FAILED.GetEventTested
        OpEventGetEventTested_GetEventTested_EvtInfo_AutoCreatedDemEvent_FlsConfigSet_FLS_E_HW_FAILURE: start-on-event=GetEventTested, operation=EvtInfo_AutoCreatedDemEvent_FlsConfigSet_FLS_E_HW_FAILURE.GetEventTested
        OpEventGetEventTested_GetEventTested_EvtInfo_AutoCreatedDemEvent_FlsConfigSet_FLS_E_INT_INCONSISTENT: start-on-event=GetEventTested, operation=EvtInfo_AutoCreatedDemEvent_FlsConfigSet_FLS_E_INT_INCONSISTENT.GetEventTested
        OpEventGetEventTested_GetEventTested_EvtInfo_AutoCreatedDemEvent_FlsConfigSet_FLS_E_READ_FAILED_DED: start-on-event=GetEventTested, operation=EvtInfo_AutoCreatedDemEvent_FlsConfigSet_FLS_E_READ_FAILED_DED.GetEventTested
        OpEventGetEventTested_GetEventTested_EvtInfo_AutoCreatedDemEvent_FlsConfigSet_FLS_E_REG_WRITE_VERIFY: start-on-event=GetEventTested, operation=EvtInfo_AutoCreatedDemEvent_FlsConfigSet_FLS_E_REG_WRITE_VERIFY.GetEventTested
        OpEventGetDTCOfEvent_GetDTCOfEvent_GeneralEventInfo: start-on-event=GetDTCOfEvent, operation=GeneralEventInfo.GetDTCOfEvent
        OpEventGetDTCOfEvent_GetDTCOfEvent_EvtInfo_AutoCreatedDemEvent_FlsConfigSet_FLS_E_COMPARE_FAILED: start-on-event=GetDTCOfEvent, operation=EvtInfo_AutoCreatedDemEvent_FlsConfigSet_FLS_E_COMPARE_FAILED.GetDTCOfEvent
        OpEventGetDTCOfEvent_GetDTCOfEvent_EvtInfo_AutoCreatedDemEvent_FlsConfigSet_FLS_E_UNEXPECTED_FLASH_ID: start-on-event=GetDTCOfEvent, operation=EvtInfo_AutoCreatedDemEvent_FlsConfigSet_FLS_E_UNEXPECTED_FLASH_ID.GetDTCOfEvent
        OpEventGetDTCOfEvent_GetDTCOfEvent_EvtInfo_AutoCreatedDemEvent_FlsConfigSet_FLS_E_WRITE_FAILED: start-on-event=GetDTCOfEvent, operation=EvtInfo_AutoCreatedDemEvent_FlsConfigSet_FLS_E_WRITE_FAILED.GetDTCOfEvent
        OpEventGetDTCOfEvent_GetDTCOfEvent_EvtInfo_AutoCreatedDemEvent_FlsConfigSet_FLS_E_READ_FAILED: start-on-event=GetDTCOfEvent, operation=EvtInfo_AutoCreatedDemEvent_FlsConfigSet_FLS_E_READ_FAILED.GetDTCOfEvent
        OpEventGetDTCOfEvent_GetDTCOfEvent_EvtInfo_AutoCreatedDemEvent_FlsConfigSet_FLS_E_ERASE_FAILED: start-on-event=GetDTCOfEvent, operation=EvtInfo_AutoCreatedDemEvent_FlsConfigSet_FLS_E_ERASE_FAILED.GetDTCOfEvent
        OpEventGetDTCOfEvent_GetDTCOfEvent_EvtInfo_AutoCreatedDemEvent_FlsConfigSet_FLS_E_HW_FAILURE: start-on-event=GetDTCOfEvent, operation=EvtInfo_AutoCreatedDemEvent_FlsConfigSet_FLS_E_HW_FAILURE.GetDTCOfEvent
        OpEventGetDTCOfEvent_GetDTCOfEvent_EvtInfo_AutoCreatedDemEvent_FlsConfigSet_FLS_E_INT_INCONSISTENT: start-on-event=GetDTCOfEvent, operation=EvtInfo_AutoCreatedDemEvent_FlsConfigSet_FLS_E_INT_INCONSISTENT.GetDTCOfEvent
        OpEventGetDTCOfEvent_GetDTCOfEvent_EvtInfo_AutoCreatedDemEvent_FlsConfigSet_FLS_E_READ_FAILED_DED: start-on-event=GetDTCOfEvent, operation=EvtInfo_AutoCreatedDemEvent_FlsConfigSet_FLS_E_READ_FAILED_DED.GetDTCOfEvent
        OpEventGetDTCOfEvent_GetDTCOfEvent_EvtInfo_AutoCreatedDemEvent_FlsConfigSet_FLS_E_REG_WRITE_VERIFY: start-on-event=GetDTCOfEvent, operation=EvtInfo_AutoCreatedDemEvent_FlsConfigSet_FLS_E_REG_WRITE_VERIFY.GetDTCOfEvent
        OpEventGetFaultDetectionCounter_GetFaultDetectionCounter_GeneralEventInfo: start-on-event=GetFaultDetectionCounter, operation=GeneralEventInfo.GetFaultDetectionCounter
        OpEventGetFaultDetectionCounter_GetFaultDetectionCounter_EvtInfo_AutoCreatedDemEvent_FlsConfigSet_FLS_E_COMPARE_FAILED: start-on-event=GetFaultDetectionCounter, operation=EvtInfo_AutoCreatedDemEvent_FlsConfigSet_FLS_E_COMPARE_FAILED.GetFaultDetectionCounter
        OpEventGetFaultDetectionCounter_GetFaultDetectionCounter_EvtInfo_AutoCreatedDemEvent_FlsConfigSet_FLS_E_UNEXPECTED_FLASH_ID: start-on-event=GetFaultDetectionCounter, operation=EvtInfo_AutoCreatedDemEvent_FlsConfigSet_FLS_E_UNEXPECTED_FLASH_ID.GetFaultDetectionCounter
        OpEventGetFaultDetectionCounter_GetFaultDetectionCounter_EvtInfo_AutoCreatedDemEvent_FlsConfigSet_FLS_E_WRITE_FAILED: start-on-event=GetFaultDetectionCounter, operation=EvtInfo_AutoCreatedDemEvent_FlsConfigSet_FLS_E_WRITE_FAILED.GetFaultDetectionCounter
        OpEventGetFaultDetectionCounter_GetFaultDetectionCounter_EvtInfo_AutoCreatedDemEvent_FlsConfigSet_FLS_E_READ_FAILED: start-on-event=GetFaultDetectionCounter, operation=EvtInfo_AutoCreatedDemEvent_FlsConfigSet_FLS_E_READ_FAILED.GetFaultDetectionCounter
        OpEventGetFaultDetectionCounter_GetFaultDetectionCounter_EvtInfo_AutoCreatedDemEvent_FlsConfigSet_FLS_E_ERASE_FAILED: start-on-event=GetFaultDetectionCounter, operation=EvtInfo_AutoCreatedDemEvent_FlsConfigSet_FLS_E_ERASE_FAILED.GetFaultDetectionCounter
        OpEventGetFaultDetectionCounter_GetFaultDetectionCounter_EvtInfo_AutoCreatedDemEvent_FlsConfigSet_FLS_E_HW_FAILURE: start-on-event=GetFaultDetectionCounter, operation=EvtInfo_AutoCreatedDemEvent_FlsConfigSet_FLS_E_HW_FAILURE.GetFaultDetectionCounter
        OpEventGetFaultDetectionCounter_GetFaultDetectionCounter_EvtInfo_AutoCreatedDemEvent_FlsConfigSet_FLS_E_INT_INCONSISTENT: start-on-event=GetFaultDetectionCounter, operation=EvtInfo_AutoCreatedDemEvent_FlsConfigSet_FLS_E_INT_INCONSISTENT.GetFaultDetectionCounter
        OpEventGetFaultDetectionCounter_GetFaultDetectionCounter_EvtInfo_AutoCreatedDemEvent_FlsConfigSet_FLS_E_READ_FAILED_DED: start-on-event=GetFaultDetectionCounter, operation=EvtInfo_AutoCreatedDemEvent_FlsConfigSet_FLS_E_READ_FAILED_DED.GetFaultDetectionCounter
        OpEventGetFaultDetectionCounter_GetFaultDetectionCounter_EvtInfo_AutoCreatedDemEvent_FlsConfigSet_FLS_E_REG_WRITE_VERIFY: start-on-event=GetFaultDetectionCounter, operation=EvtInfo_AutoCreatedDemEvent_FlsConfigSet_FLS_E_REG_WRITE_VERIFY.GetFaultDetectionCounter
        OpEventGetEventFreezeFrameData_GetEventFreezeFrameData_GeneralEventInfo: start-on-event=GetEventFreezeFrameData, operation=GeneralEventInfo.GetEventFreezeFrameData
        OpEventGetEventFreezeFrameData_GetEventFreezeFrameData_EvtInfo_AutoCreatedDemEvent_FlsConfigSet_FLS_E_COMPARE_FAILED: start-on-event=GetEventFreezeFrameData, operation=EvtInfo_AutoCreatedDemEvent_FlsConfigSet_FLS_E_COMPARE_FAILED.GetEventFreezeFrameData
        OpEventGetEventFreezeFrameData_GetEventFreezeFrameData_EvtInfo_AutoCreatedDemEvent_FlsConfigSet_FLS_E_UNEXPECTED_FLASH_ID: start-on-event=GetEventFreezeFrameData, operation=EvtInfo_AutoCreatedDemEvent_FlsConfigSet_FLS_E_UNEXPECTED_FLASH_ID.GetEventFreezeFrameData
        OpEventGetEventFreezeFrameData_GetEventFreezeFrameData_EvtInfo_AutoCreatedDemEvent_FlsConfigSet_FLS_E_WRITE_FAILED: start-on-event=GetEventFreezeFrameData, operation=EvtInfo_AutoCreatedDemEvent_FlsConfigSet_FLS_E_WRITE_FAILED.GetEventFreezeFrameData
        OpEventGetEventFreezeFrameData_GetEventFreezeFrameData_EvtInfo_AutoCreatedDemEvent_FlsConfigSet_FLS_E_READ_FAILED: start-on-event=GetEventFreezeFrameData, operation=EvtInfo_AutoCreatedDemEvent_FlsConfigSet_FLS_E_READ_FAILED.GetEventFreezeFrameData
        OpEventGetEventFreezeFrameData_GetEventFreezeFrameData_EvtInfo_AutoCreatedDemEvent_FlsConfigSet_FLS_E_ERASE_FAILED: start-on-event=GetEventFreezeFrameData, operation=EvtInfo_AutoCreatedDemEvent_FlsConfigSet_FLS_E_ERASE_FAILED.GetEventFreezeFrameData
        OpEventGetEventFreezeFrameData_GetEventFreezeFrameData_EvtInfo_AutoCreatedDemEvent_FlsConfigSet_FLS_E_HW_FAILURE: start-on-event=GetEventFreezeFrameData, operation=EvtInfo_AutoCreatedDemEvent_FlsConfigSet_FLS_E_HW_FAILURE.GetEventFreezeFrameData
        OpEventGetEventFreezeFrameData_GetEventFreezeFrameData_EvtInfo_AutoCreatedDemEvent_FlsConfigSet_FLS_E_INT_INCONSISTENT: start-on-event=GetEventFreezeFrameData, operation=EvtInfo_AutoCreatedDemEvent_FlsConfigSet_FLS_E_INT_INCONSISTENT.GetEventFreezeFrameData
        OpEventGetEventFreezeFrameData_GetEventFreezeFrameData_EvtInfo_AutoCreatedDemEvent_FlsConfigSet_FLS_E_READ_FAILED_DED: start-on-event=GetEventFreezeFrameData, operation=EvtInfo_AutoCreatedDemEvent_FlsConfigSet_FLS_E_READ_FAILED_DED.GetEventFreezeFrameData
        OpEventGetEventFreezeFrameData_GetEventFreezeFrameData_EvtInfo_AutoCreatedDemEvent_FlsConfigSet_FLS_E_REG_WRITE_VERIFY: start-on-event=GetEventFreezeFrameData, operation=EvtInfo_AutoCreatedDemEvent_FlsConfigSet_FLS_E_REG_WRITE_VERIFY.GetEventFreezeFrameData
        OpEventGetEventExtendedDataRecord_GetEventExtendedDataRecord_GeneralEventInfo: start-on-event=GetEventExtendedDataRecord, operation=GeneralEventInfo.GetEventExtendedDataRecord
        OpEventGetEventExtendedDataRecord_GetEventExtendedDataRecord_EvtInfo_AutoCreatedDemEvent_FlsConfigSet_FLS_E_COMPARE_FAILED: start-on-event=GetEventExtendedDataRecord, operation=EvtInfo_AutoCreatedDemEvent_FlsConfigSet_FLS_E_COMPARE_FAILED.GetEventExtendedDataRecord
        OpEventGetEventExtendedDataRecord_GetEventExtendedDataRecord_EvtInfo_AutoCreatedDemEvent_FlsConfigSet_FLS_E_UNEXPECTED_FLASH_ID: start-on-event=GetEventExtendedDataRecord, operation=EvtInfo_AutoCreatedDemEvent_FlsConfigSet_FLS_E_UNEXPECTED_FLASH_ID.GetEventExtendedDataRecord
        OpEventGetEventExtendedDataRecord_GetEventExtendedDataRecord_EvtInfo_AutoCreatedDemEvent_FlsConfigSet_FLS_E_WRITE_FAILED: start-on-event=GetEventExtendedDataRecord, operation=EvtInfo_AutoCreatedDemEvent_FlsConfigSet_FLS_E_WRITE_FAILED.GetEventExtendedDataRecord
        OpEventGetEventExtendedDataRecord_GetEventExtendedDataRecord_EvtInfo_AutoCreatedDemEvent_FlsConfigSet_FLS_E_READ_FAILED: start-on-event=GetEventExtendedDataRecord, operation=EvtInfo_AutoCreatedDemEvent_FlsConfigSet_FLS_E_READ_FAILED.GetEventExtendedDataRecord
        OpEventGetEventExtendedDataRecord_GetEventExtendedDataRecord_EvtInfo_AutoCreatedDemEvent_FlsConfigSet_FLS_E_ERASE_FAILED: start-on-event=GetEventExtendedDataRecord, operation=EvtInfo_AutoCreatedDemEvent_FlsConfigSet_FLS_E_ERASE_FAILED.GetEventExtendedDataRecord
        OpEventGetEventExtendedDataRecord_GetEventExtendedDataRecord_EvtInfo_AutoCreatedDemEvent_FlsConfigSet_FLS_E_HW_FAILURE: start-on-event=GetEventExtendedDataRecord, operation=EvtInfo_AutoCreatedDemEvent_FlsConfigSet_FLS_E_HW_FAILURE.GetEventExtendedDataRecord
        OpEventGetEventExtendedDataRecord_GetEventExtendedDataRecord_EvtInfo_AutoCreatedDemEvent_FlsConfigSet_FLS_E_INT_INCONSISTENT: start-on-event=GetEventExtendedDataRecord, operation=EvtInfo_AutoCreatedDemEvent_FlsConfigSet_FLS_E_INT_INCONSISTENT.GetEventExtendedDataRecord
        OpEventGetEventExtendedDataRecord_GetEventExtendedDataRecord_EvtInfo_AutoCreatedDemEvent_FlsConfigSet_FLS_E_READ_FAILED_DED: start-on-event=GetEventExtendedDataRecord, operation=EvtInfo_AutoCreatedDemEvent_FlsConfigSet_FLS_E_READ_FAILED_DED.GetEventExtendedDataRecord
        OpEventGetEventExtendedDataRecord_GetEventExtendedDataRecord_EvtInfo_AutoCreatedDemEvent_FlsConfigSet_FLS_E_REG_WRITE_VERIFY: start-on-event=GetEventExtendedDataRecord, operation=EvtInfo_AutoCreatedDemEvent_FlsConfigSet_FLS_E_REG_WRITE_VERIFY.GetEventExtendedDataRecord
        OpEventGetEventEnableCondition_GetEventEnableCondition_GeneralEventInfo: start-on-event=GetEventEnableCondition, operation=GeneralEventInfo.GetEventEnableCondition
        OpEventGetEventEnableCondition_GetEventEnableCondition_EvtInfo_AutoCreatedDemEvent_FlsConfigSet_FLS_E_COMPARE_FAILED: start-on-event=GetEventEnableCondition, operation=EvtInfo_AutoCreatedDemEvent_FlsConfigSet_FLS_E_COMPARE_FAILED.GetEventEnableCondition
        OpEventGetEventEnableCondition_GetEventEnableCondition_EvtInfo_AutoCreatedDemEvent_FlsConfigSet_FLS_E_UNEXPECTED_FLASH_ID: start-on-event=GetEventEnableCondition, operation=EvtInfo_AutoCreatedDemEvent_FlsConfigSet_FLS_E_UNEXPECTED_FLASH_ID.GetEventEnableCondition
        OpEventGetEventEnableCondition_GetEventEnableCondition_EvtInfo_AutoCreatedDemEvent_FlsConfigSet_FLS_E_WRITE_FAILED: start-on-event=GetEventEnableCondition, operation=EvtInfo_AutoCreatedDemEvent_FlsConfigSet_FLS_E_WRITE_FAILED.GetEventEnableCondition
        OpEventGetEventEnableCondition_GetEventEnableCondition_EvtInfo_AutoCreatedDemEvent_FlsConfigSet_FLS_E_READ_FAILED: start-on-event=GetEventEnableCondition, operation=EvtInfo_AutoCreatedDemEvent_FlsConfigSet_FLS_E_READ_FAILED.GetEventEnableCondition
        OpEventGetEventEnableCondition_GetEventEnableCondition_EvtInfo_AutoCreatedDemEvent_FlsConfigSet_FLS_E_ERASE_FAILED: start-on-event=GetEventEnableCondition, operation=EvtInfo_AutoCreatedDemEvent_FlsConfigSet_FLS_E_ERASE_FAILED.GetEventEnableCondition
        OpEventGetEventEnableCondition_GetEventEnableCondition_EvtInfo_AutoCreatedDemEvent_FlsConfigSet_FLS_E_HW_FAILURE: start-on-event=GetEventEnableCondition, operation=EvtInfo_AutoCreatedDemEvent_FlsConfigSet_FLS_E_HW_FAILURE.GetEventEnableCondition
        OpEventGetEventEnableCondition_GetEventEnableCondition_EvtInfo_AutoCreatedDemEvent_FlsConfigSet_FLS_E_INT_INCONSISTENT: start-on-event=GetEventEnableCondition, operation=EvtInfo_AutoCreatedDemEvent_FlsConfigSet_FLS_E_INT_INCONSISTENT.GetEventEnableCondition
        OpEventGetEventEnableCondition_GetEventEnableCondition_EvtInfo_AutoCreatedDemEvent_FlsConfigSet_FLS_E_READ_FAILED_DED: start-on-event=GetEventEnableCondition, operation=EvtInfo_AutoCreatedDemEvent_FlsConfigSet_FLS_E_READ_FAILED_DED.GetEventEnableCondition
        OpEventGetEventEnableCondition_GetEventEnableCondition_EvtInfo_AutoCreatedDemEvent_FlsConfigSet_FLS_E_REG_WRITE_VERIFY: start-on-event=GetEventEnableCondition, operation=EvtInfo_AutoCreatedDemEvent_FlsConfigSet_FLS_E_REG_WRITE_VERIFY.GetEventEnableCondition
        OpEventGetDebouncingOfEvent_GetDebouncingOfEvent_GeneralEventInfo: start-on-event=GetDebouncingOfEvent, operation=GeneralEventInfo.GetDebouncingOfEvent
        OpEventGetDebouncingOfEvent_GetDebouncingOfEvent_EvtInfo_AutoCreatedDemEvent_FlsConfigSet_FLS_E_COMPARE_FAILED: start-on-event=GetDebouncingOfEvent, operation=EvtInfo_AutoCreatedDemEvent_FlsConfigSet_FLS_E_COMPARE_FAILED.GetDebouncingOfEvent
        OpEventGetDebouncingOfEvent_GetDebouncingOfEvent_EvtInfo_AutoCreatedDemEvent_FlsConfigSet_FLS_E_UNEXPECTED_FLASH_ID: start-on-event=GetDebouncingOfEvent, operation=EvtInfo_AutoCreatedDemEvent_FlsConfigSet_FLS_E_UNEXPECTED_FLASH_ID.GetDebouncingOfEvent
        OpEventGetDebouncingOfEvent_GetDebouncingOfEvent_EvtInfo_AutoCreatedDemEvent_FlsConfigSet_FLS_E_WRITE_FAILED: start-on-event=GetDebouncingOfEvent, operation=EvtInfo_AutoCreatedDemEvent_FlsConfigSet_FLS_E_WRITE_FAILED.GetDebouncingOfEvent
        OpEventGetDebouncingOfEvent_GetDebouncingOfEvent_EvtInfo_AutoCreatedDemEvent_FlsConfigSet_FLS_E_READ_FAILED: start-on-event=GetDebouncingOfEvent, operation=EvtInfo_AutoCreatedDemEvent_FlsConfigSet_FLS_E_READ_FAILED.GetDebouncingOfEvent
        OpEventGetDebouncingOfEvent_GetDebouncingOfEvent_EvtInfo_AutoCreatedDemEvent_FlsConfigSet_FLS_E_ERASE_FAILED: start-on-event=GetDebouncingOfEvent, operation=EvtInfo_AutoCreatedDemEvent_FlsConfigSet_FLS_E_ERASE_FAILED.GetDebouncingOfEvent
        OpEventGetDebouncingOfEvent_GetDebouncingOfEvent_EvtInfo_AutoCreatedDemEvent_FlsConfigSet_FLS_E_HW_FAILURE: start-on-event=GetDebouncingOfEvent, operation=EvtInfo_AutoCreatedDemEvent_FlsConfigSet_FLS_E_HW_FAILURE.GetDebouncingOfEvent
        OpEventGetDebouncingOfEvent_GetDebouncingOfEvent_EvtInfo_AutoCreatedDemEvent_FlsConfigSet_FLS_E_INT_INCONSISTENT: start-on-event=GetDebouncingOfEvent, operation=EvtInfo_AutoCreatedDemEvent_FlsConfigSet_FLS_E_INT_INCONSISTENT.GetDebouncingOfEvent
        OpEventGetDebouncingOfEvent_GetDebouncingOfEvent_EvtInfo_AutoCreatedDemEvent_FlsConfigSet_FLS_E_READ_FAILED_DED: start-on-event=GetDebouncingOfEvent, operation=EvtInfo_AutoCreatedDemEvent_FlsConfigSet_FLS_E_READ_FAILED_DED.GetDebouncingOfEvent
        OpEventGetDebouncingOfEvent_GetDebouncingOfEvent_EvtInfo_AutoCreatedDemEvent_FlsConfigSet_FLS_E_REG_WRITE_VERIFY: start-on-event=GetDebouncingOfEvent, operation=EvtInfo_AutoCreatedDemEvent_FlsConfigSet_FLS_E_REG_WRITE_VERIFY.GetDebouncingOfEvent
        OpEventDcmClearDTC_DcmClearDTC_Dcm: start-on-event=DcmClearDTC, operation=Dcm.DcmClearDTC
        OpEventDcmGetNextFilteredDTCAndFDC_DcmGetNextFilteredDTCAndFDC_Dcm: start-on-event=DcmGetNextFilteredDTCAndFDC, operation=Dcm.DcmGetNextFilteredDTCAndFDC
        OpEventDcmEnableDTCSetting_DcmEnableDTCSetting_Dcm: start-on-event=DcmEnableDTCSetting, operation=Dcm.DcmEnableDTCSetting
        OpEventDcmGetFreezeFrameDataByDTC_DcmGetFreezeFrameDataByDTC_Dcm: start-on-event=DcmGetFreezeFrameDataByDTC, operation=Dcm.DcmGetFreezeFrameDataByDTC
        OpEventDcmGetExtendedDataRecordByDTC_DcmGetExtendedDataRecordByDTC_Dcm: start-on-event=DcmGetExtendedDataRecordByDTC, operation=Dcm.DcmGetExtendedDataRecordByDTC
        OpEventSetOperationCycleState_SetOperationCycleState_OpCycle_DemOperationCycle: start-on-event=SetOperationCycleState, operation=OpCycle_DemOperationCycle.SetOperationCycleState
        OpEventGetEventStatus_GetEventStatus_EvtInfo_AutoCreatedDemEvent_McuModuleConfiguration_MCU_E_CLOCK_FAILURE: start-on-event=GetEventStatus, operation=EvtInfo_AutoCreatedDemEvent_McuModuleConfiguration_MCU_E_CLOCK_FAILURE.GetEventStatus
        OpEventGetEventStatus_GetEventStatus_EvtInfo_AutoCreatedDemEvent_FlsConfigSet_FLS_E_ECC_FAILED: start-on-event=GetEventStatus, operation=EvtInfo_AutoCreatedDemEvent_FlsConfigSet_FLS_E_ECC_FAILED.GetEventStatus
        OpEventGetEventStatus_GetEventStatus_EvtInfo_AutoCreatedDemEvent_McuModuleConfiguration_MCU_E_RESETCONTROLLER_STARTUP_FAILURE: start-on-event=GetEventStatus, operation=EvtInfo_AutoCreatedDemEvent_McuModuleConfiguration_MCU_E_RESETCONTROLLER_STARTUP_FAILURE.GetEventStatus
        OpEventGetEventStatus_GetEventStatus_EvtInfo_AutoCreatedDemEvent_McuModuleConfiguration_MCU_E_WRITE_TIMEOUT_FAILURE: start-on-event=GetEventStatus, operation=EvtInfo_AutoCreatedDemEvent_McuModuleConfiguration_MCU_E_WRITE_TIMEOUT_FAILURE.GetEventStatus
        OpEventGetEventStatus_GetEventStatus_EvtInfo_AutoCreatedDemEvent_PortModuleConfiguration_PORT_E_WRITE_TIMEOUT_FAILURE: start-on-event=GetEventStatus, operation=EvtInfo_AutoCreatedDemEvent_PortModuleConfiguration_PORT_E_WRITE_TIMEOUT_FAILURE.GetEventStatus
        OpEventGetEventFailed_GetEventFailed_EvtInfo_AutoCreatedDemEvent_McuModuleConfiguration_MCU_E_CLOCK_FAILURE: start-on-event=GetEventFailed, operation=EvtInfo_AutoCreatedDemEvent_McuModuleConfiguration_MCU_E_CLOCK_FAILURE.GetEventFailed
        OpEventGetEventFailed_GetEventFailed_EvtInfo_AutoCreatedDemEvent_FlsConfigSet_FLS_E_ECC_FAILED: start-on-event=GetEventFailed, operation=EvtInfo_AutoCreatedDemEvent_FlsConfigSet_FLS_E_ECC_FAILED.GetEventFailed
        OpEventGetEventFailed_GetEventFailed_EvtInfo_AutoCreatedDemEvent_McuModuleConfiguration_MCU_E_RESETCONTROLLER_STARTUP_FAILURE: start-on-event=GetEventFailed, operation=EvtInfo_AutoCreatedDemEvent_McuModuleConfiguration_MCU_E_RESETCONTROLLER_STARTUP_FAILURE.GetEventFailed
        OpEventGetEventFailed_GetEventFailed_EvtInfo_AutoCreatedDemEvent_McuModuleConfiguration_MCU_E_WRITE_TIMEOUT_FAILURE: start-on-event=GetEventFailed, operation=EvtInfo_AutoCreatedDemEvent_McuModuleConfiguration_MCU_E_WRITE_TIMEOUT_FAILURE.GetEventFailed
        OpEventGetEventFailed_GetEventFailed_EvtInfo_AutoCreatedDemEvent_PortModuleConfiguration_PORT_E_WRITE_TIMEOUT_FAILURE: start-on-event=GetEventFailed, operation=EvtInfo_AutoCreatedDemEvent_PortModuleConfiguration_PORT_E_WRITE_TIMEOUT_FAILURE.GetEventFailed
        OpEventGetEventTested_GetEventTested_EvtInfo_AutoCreatedDemEvent_McuModuleConfiguration_MCU_E_CLOCK_FAILURE: start-on-event=GetEventTested, operation=EvtInfo_AutoCreatedDemEvent_McuModuleConfiguration_MCU_E_CLOCK_FAILURE.GetEventTested
        OpEventGetEventTested_GetEventTested_EvtInfo_AutoCreatedDemEvent_FlsConfigSet_FLS_E_ECC_FAILED: start-on-event=GetEventTested, operation=EvtInfo_AutoCreatedDemEvent_FlsConfigSet_FLS_E_ECC_FAILED.GetEventTested
        OpEventGetEventTested_GetEventTested_EvtInfo_AutoCreatedDemEvent_McuModuleConfiguration_MCU_E_RESETCONTROLLER_STARTUP_FAILURE: start-on-event=GetEventTested, operation=EvtInfo_AutoCreatedDemEvent_McuModuleConfiguration_MCU_E_RESETCONTROLLER_STARTUP_FAILURE.GetEventTested
        OpEventGetEventTested_GetEventTested_EvtInfo_AutoCreatedDemEvent_McuModuleConfiguration_MCU_E_WRITE_TIMEOUT_FAILURE: start-on-event=GetEventTested, operation=EvtInfo_AutoCreatedDemEvent_McuModuleConfiguration_MCU_E_WRITE_TIMEOUT_FAILURE.GetEventTested
        OpEventGetEventTested_GetEventTested_EvtInfo_AutoCreatedDemEvent_PortModuleConfiguration_PORT_E_WRITE_TIMEOUT_FAILURE: start-on-event=GetEventTested, operation=EvtInfo_AutoCreatedDemEvent_PortModuleConfiguration_PORT_E_WRITE_TIMEOUT_FAILURE.GetEventTested
        OpEventGetDTCOfEvent_GetDTCOfEvent_EvtInfo_AutoCreatedDemEvent_McuModuleConfiguration_MCU_E_CLOCK_FAILURE: start-on-event=GetDTCOfEvent, operation=EvtInfo_AutoCreatedDemEvent_McuModuleConfiguration_MCU_E_CLOCK_FAILURE.GetDTCOfEvent
        OpEventGetDTCOfEvent_GetDTCOfEvent_EvtInfo_AutoCreatedDemEvent_FlsConfigSet_FLS_E_ECC_FAILED: start-on-event=GetDTCOfEvent, operation=EvtInfo_AutoCreatedDemEvent_FlsConfigSet_FLS_E_ECC_FAILED.GetDTCOfEvent
        OpEventGetDTCOfEvent_GetDTCOfEvent_EvtInfo_AutoCreatedDemEvent_McuModuleConfiguration_MCU_E_RESETCONTROLLER_STARTUP_FAILURE: start-on-event=GetDTCOfEvent, operation=EvtInfo_AutoCreatedDemEvent_McuModuleConfiguration_MCU_E_RESETCONTROLLER_STARTUP_FAILURE.GetDTCOfEvent
        OpEventGetDTCOfEvent_GetDTCOfEvent_EvtInfo_AutoCreatedDemEvent_McuModuleConfiguration_MCU_E_WRITE_TIMEOUT_FAILURE: start-on-event=GetDTCOfEvent, operation=EvtInfo_AutoCreatedDemEvent_McuModuleConfiguration_MCU_E_WRITE_TIMEOUT_FAILURE.GetDTCOfEvent
        OpEventGetDTCOfEvent_GetDTCOfEvent_EvtInfo_AutoCreatedDemEvent_PortModuleConfiguration_PORT_E_WRITE_TIMEOUT_FAILURE: start-on-event=GetDTCOfEvent, operation=EvtInfo_AutoCreatedDemEvent_PortModuleConfiguration_PORT_E_WRITE_TIMEOUT_FAILURE.GetDTCOfEvent
        OpEventGetFaultDetectionCounter_GetFaultDetectionCounter_EvtInfo_AutoCreatedDemEvent_McuModuleConfiguration_MCU_E_CLOCK_FAILURE: start-on-event=GetFaultDetectionCounter, operation=EvtInfo_AutoCreatedDemEvent_McuModuleConfiguration_MCU_E_CLOCK_FAILURE.GetFaultDetectionCounter
        OpEventGetFaultDetectionCounter_GetFaultDetectionCounter_EvtInfo_AutoCreatedDemEvent_FlsConfigSet_FLS_E_ECC_FAILED: start-on-event=GetFaultDetectionCounter, operation=EvtInfo_AutoCreatedDemEvent_FlsConfigSet_FLS_E_ECC_FAILED.GetFaultDetectionCounter
        OpEventGetFaultDetectionCounter_GetFaultDetectionCounter_EvtInfo_AutoCreatedDemEvent_McuModuleConfiguration_MCU_E_RESET_91721255: start-on-event=GetFaultDetectionCounter, operation=EvtInfo_AutoCreatedDemEvent_McuModuleConfiguration_MCU_E_RESETCONTROLLER_STARTUP_FAILURE.GetFaultDetectionCounter
        OpEventGetFaultDetectionCounter_GetFaultDetectionCounter_EvtInfo_AutoCreatedDemEvent_McuModuleConfiguration_MCU_E_WRITE_10a4598a: start-on-event=GetFaultDetectionCounter, operation=EvtInfo_AutoCreatedDemEvent_McuModuleConfiguration_MCU_E_WRITE_TIMEOUT_FAILURE.GetFaultDetectionCounter
        OpEventGetFaultDetectionCounter_GetFaultDetectionCounter_EvtInfo_AutoCreatedDemEvent_PortModuleConfiguration_PORT_E_WRI_6f00b0dd: start-on-event=GetFaultDetectionCounter, operation=EvtInfo_AutoCreatedDemEvent_PortModuleConfiguration_PORT_E_WRITE_TIMEOUT_FAILURE.GetFaultDetectionCounter
        OpEventGetEventFreezeFrameData_GetEventFreezeFrameData_EvtInfo_AutoCreatedDemEvent_McuModuleConfiguration_MCU_E_CLOCK_FAILURE: start-on-event=GetEventFreezeFrameData, operation=EvtInfo_AutoCreatedDemEvent_McuModuleConfiguration_MCU_E_CLOCK_FAILURE.GetEventFreezeFrameData
        OpEventGetEventFreezeFrameData_GetEventFreezeFrameData_EvtInfo_AutoCreatedDemEvent_FlsConfigSet_FLS_E_ECC_FAILED: start-on-event=GetEventFreezeFrameData, operation=EvtInfo_AutoCreatedDemEvent_FlsConfigSet_FLS_E_ECC_FAILED.GetEventFreezeFrameData
        OpEventGetEventFreezeFrameData_GetEventFreezeFrameData_EvtInfo_AutoCreatedDemEvent_McuModuleConfiguration_MCU_E_RESETCO_f328b8ef: start-on-event=GetEventFreezeFrameData, operation=EvtInfo_AutoCreatedDemEvent_McuModuleConfiguration_MCU_E_RESETCONTROLLER_STARTUP_FAILURE.GetEventFreezeFrameData
        OpEventGetEventFreezeFrameData_GetEventFreezeFrameData_EvtInfo_AutoCreatedDemEvent_McuModuleConfiguration_MCU_E_WRITE_T_c289301c: start-on-event=GetEventFreezeFrameData, operation=EvtInfo_AutoCreatedDemEvent_McuModuleConfiguration_MCU_E_WRITE_TIMEOUT_FAILURE.GetEventFreezeFrameData
        OpEventGetEventFreezeFrameData_GetEventFreezeFrameData_EvtInfo_AutoCreatedDemEvent_PortModuleConfiguration_PORT_E_WRITE_7c759690: start-on-event=GetEventFreezeFrameData, operation=EvtInfo_AutoCreatedDemEvent_PortModuleConfiguration_PORT_E_WRITE_TIMEOUT_FAILURE.GetEventFreezeFrameData
        OpEventGetEventExtendedDataRecord_GetEventExtendedDataRecord_EvtInfo_AutoCreatedDemEvent_McuModuleConfiguration_MCU_E_C_9cd3cb4c: start-on-event=GetEventExtendedDataRecord, operation=EvtInfo_AutoCreatedDemEvent_McuModuleConfiguration_MCU_E_CLOCK_FAILURE.GetEventExtendedDataRecord
        OpEventGetEventExtendedDataRecord_GetEventExtendedDataRecord_EvtInfo_AutoCreatedDemEvent_FlsConfigSet_FLS_E_ECC_FAILED: start-on-event=GetEventExtendedDataRecord, operation=EvtInfo_AutoCreatedDemEvent_FlsConfigSet_FLS_E_ECC_FAILED.GetEventExtendedDataRecord
        OpEventGetEventExtendedDataRecord_GetEventExtendedDataRecord_EvtInfo_AutoCreatedDemEvent_McuModuleConfiguration_MCU_E_R_26066ef0: start-on-event=GetEventExtendedDataRecord, operation=EvtInfo_AutoCreatedDemEvent_McuModuleConfiguration_MCU_E_RESETCONTROLLER_STARTUP_FAILURE.GetEventExtendedDataRecord
        OpEventGetEventExtendedDataRecord_GetEventExtendedDataRecord_EvtInfo_AutoCreatedDemEvent_McuModuleConfiguration_MCU_E_W_7e2746e2: start-on-event=GetEventExtendedDataRecord, operation=EvtInfo_AutoCreatedDemEvent_McuModuleConfiguration_MCU_E_WRITE_TIMEOUT_FAILURE.GetEventExtendedDataRecord
        OpEventGetEventExtendedDataRecord_GetEventExtendedDataRecord_EvtInfo_AutoCreatedDemEvent_PortModuleConfiguration_PORT_E_4f2c3204: start-on-event=GetEventExtendedDataRecord, operation=EvtInfo_AutoCreatedDemEvent_PortModuleConfiguration_PORT_E_WRITE_TIMEOUT_FAILURE.GetEventExtendedDataRecord
        OpEventGetEventEnableCondition_GetEventEnableCondition_EvtInfo_AutoCreatedDemEvent_McuModuleConfiguration_MCU_E_CLOCK_FAILURE: start-on-event=GetEventEnableCondition, operation=EvtInfo_AutoCreatedDemEvent_McuModuleConfiguration_MCU_E_CLOCK_FAILURE.GetEventEnableCondition
        OpEventGetEventEnableCondition_GetEventEnableCondition_EvtInfo_AutoCreatedDemEvent_FlsConfigSet_FLS_E_ECC_FAILED: start-on-event=GetEventEnableCondition, operation=EvtInfo_AutoCreatedDemEvent_FlsConfigSet_FLS_E_ECC_FAILED.GetEventEnableCondition
        OpEventGetEventEnableCondition_GetEventEnableCondition_EvtInfo_AutoCreatedDemEvent_McuModuleConfiguration_MCU_E_RESETCO_9c1d360a: start-on-event=GetEventEnableCondition, operation=EvtInfo_AutoCreatedDemEvent_McuModuleConfiguration_MCU_E_RESETCONTROLLER_STARTUP_FAILURE.GetEventEnableCondition
        OpEventGetEventEnableCondition_GetEventEnableCondition_EvtInfo_AutoCreatedDemEvent_McuModuleConfiguration_MCU_E_WRITE_T_a2e88142: start-on-event=GetEventEnableCondition, operation=EvtInfo_AutoCreatedDemEvent_McuModuleConfiguration_MCU_E_WRITE_TIMEOUT_FAILURE.GetEventEnableCondition
        OpEventGetEventEnableCondition_GetEventEnableCondition_EvtInfo_AutoCreatedDemEvent_PortModuleConfiguration_PORT_E_WRITE_e42b0531: start-on-event=GetEventEnableCondition, operation=EvtInfo_AutoCreatedDemEvent_PortModuleConfiguration_PORT_E_WRITE_TIMEOUT_FAILURE.GetEventEnableCondition
        OpEventGetDebouncingOfEvent_GetDebouncingOfEvent_EvtInfo_AutoCreatedDemEvent_McuModuleConfiguration_MCU_E_CLOCK_FAILURE: start-on-event=GetDebouncingOfEvent, operation=EvtInfo_AutoCreatedDemEvent_McuModuleConfiguration_MCU_E_CLOCK_FAILURE.GetDebouncingOfEvent
        OpEventGetDebouncingOfEvent_GetDebouncingOfEvent_EvtInfo_AutoCreatedDemEvent_FlsConfigSet_FLS_E_ECC_FAILED: start-on-event=GetDebouncingOfEvent, operation=EvtInfo_AutoCreatedDemEvent_FlsConfigSet_FLS_E_ECC_FAILED.GetDebouncingOfEvent
        OpEventGetDebouncingOfEvent_GetDebouncingOfEvent_EvtInfo_AutoCreatedDemEvent_McuModuleConfiguration_MCU_E_RESETCONTROLL_9837ac5d: start-on-event=GetDebouncingOfEvent, operation=EvtInfo_AutoCreatedDemEvent_McuModuleConfiguration_MCU_E_RESETCONTROLLER_STARTUP_FAILURE.GetDebouncingOfEvent
        OpEventGetDebouncingOfEvent_GetDebouncingOfEvent_EvtInfo_AutoCreatedDemEvent_McuModuleConfiguration_MCU_E_WRITE_TIMEOUT_FAILURE: start-on-event=GetDebouncingOfEvent, operation=EvtInfo_AutoCreatedDemEvent_McuModuleConfiguration_MCU_E_WRITE_TIMEOUT_FAILURE.GetDebouncingOfEvent
        OpEventGetDebouncingOfEvent_GetDebouncingOfEvent_EvtInfo_AutoCreatedDemEvent_PortModuleConfiguration_PORT_E_WRITE_TIMEO_977c25cc: start-on-event=GetDebouncingOfEvent, operation=EvtInfo_AutoCreatedDemEvent_PortModuleConfiguration_PORT_E_WRITE_TIMEOUT_FAILURE.GetDebouncingOfEvent
      port-api-options:
        enable-take-address=true, indirect-api=false, port=Cdd
        enable-take-address=true, indirect-api=false, port=DemServices
        {enable-take-address=true, indirect-api=false, port-defined-argument-value{value=1, value-type=Dem_DTCOriginType}, port=OverflowIndPrimaryMemory}
        enable-take-address=true, indirect-api=false, port=GeneralEventInfo
        enable-take-address=true, indirect-api=false, port=Dcm
        {enable-take-address=true, indirect-api=false, port-defined-argument-value{value=0, value-type=Dem_OperationCycleIdType}, port=OpCycle_DemOperationCycle}
        {enable-take-address=true, indirect-api=false, port-defined-argument-value{value=1, value-type=Dem_EventIdType}, port=EvtInfo_AutoCreatedDemEvent_FlsConfigSet_FLS_E_COMPARE_FAILED}
        {enable-take-address=true, indirect-api=false, port-defined-argument-value{value=4, value-type=Dem_EventIdType}, port=EvtInfo_AutoCreatedDemEvent_FlsConfigSet_FLS_E_UNEXPECTED_FLASH_ID}
        {enable-take-address=true, indirect-api=false, port-defined-argument-value{value=5, value-type=Dem_EventIdType}, port=EvtInfo_AutoCreatedDemEvent_FlsConfigSet_FLS_E_WRITE_FAILED}
        {enable-take-address=true, indirect-api=false, port-defined-argument-value{value=3, value-type=Dem_EventIdType}, port=EvtInfo_AutoCreatedDemEvent_FlsConfigSet_FLS_E_READ_FAILED}
        {enable-take-address=true, indirect-api=false, port-defined-argument-value{value=2, value-type=Dem_EventIdType}, port=EvtInfo_AutoCreatedDemEvent_FlsConfigSet_FLS_E_ERASE_FAILED}
        {enable-take-address=true, indirect-api=false, port-defined-argument-value{value=10, value-type=Dem_EventIdType}, port=EvtInfo_AutoCreatedDemEvent_FlsConfigSet_FLS_E_HW_FAILURE}
        {enable-take-address=true, indirect-api=false, port-defined-argument-value{value=7, value-type=Dem_EventIdType}, port=EvtInfo_AutoCreatedDemEvent_FlsConfigSet_FLS_E_INT_INCONSISTENT}
        {enable-take-address=true, indirect-api=false, port-defined-argument-value{value=8, value-type=Dem_EventIdType}, port=EvtInfo_AutoCreatedDemEvent_FlsConfigSet_FLS_E_READ_FAILED_DED}
        {enable-take-address=true, indirect-api=false, port-defined-argument-value{value=9, value-type=Dem_EventIdType}, port=EvtInfo_AutoCreatedDemEvent_FlsConfigSet_FLS_E_REG_WRITE_VERIFY}
        {enable-take-address=true, indirect-api=false, port-defined-argument-value{value=11, value-type=Dem_EventIdType}, port=EvtInfo_AutoCreatedDemEvent_McuModuleConfiguration_MCU_E_CLOCK_FAILURE}
        {enable-take-address=true, indirect-api=false, port-defined-argument-value{value=6, value-type=Dem_EventIdType}, port=EvtInfo_AutoCreatedDemEvent_FlsConfigSet_FLS_E_ECC_FAILED}
        {enable-take-address=true, indirect-api=false, port-defined-argument-value{value=12, value-type=Dem_EventIdType}, port=EvtInfo_AutoCreatedDemEvent_McuModuleConfiguration_MCU_E_RESETCONTROLLER_STARTUP_FAILURE}
        {enable-take-address=true, indirect-api=false, port-defined-argument-value{value=13, value-type=Dem_EventIdType}, port=EvtInfo_AutoCreatedDemEvent_McuModuleConfiguration_MCU_E_WRITE_TIMEOUT_FAILURE}
        {enable-take-address=true, indirect-api=false, port-defined-argument-value{value=14, value-type=Dem_EventIdType}, port=EvtInfo_AutoCreatedDemEvent_PortModuleConfiguration_PORT_E_WRITE_TIMEOUT_FAILURE}
      21 x runnable:
        Dem_MainFunction
        ClearDTC: can-be-invoked-concurrently=true, symbol=Dem_ClearDTC
        PostRunRequested: can-be-invoked-concurrently=true, symbol=Dem_PostRunRequested
        GetDTCStatusAvailabilityMask: can-be-invoked-concurrently=true, symbol=Dem_DcmGetDTCStatusAvailabilityMask
        GetEventMemoryOverflow: can-be-invoked-concurrently=true, symbol=Dem_GetEventMemoryOverflow
        GetNumberOfEventMemoryEntries: can-be-invoked-concurrently=true, symbol=Dem_GetNumberOfEventMemoryEntries
        GetEventStatus: can-be-invoked-concurrently=true, symbol=Dem_GetEventStatus
        GetEventFailed: can-be-invoked-concurrently=true, symbol=Dem_GetEventFailed
        GetEventTested: can-be-invoked-concurrently=true, symbol=Dem_GetEventTested
        GetDTCOfEvent: can-be-invoked-concurrently=true, symbol=Dem_GetDTCOfEvent
        GetFaultDetectionCounter: can-be-invoked-concurrently=true, symbol=Dem_GetFaultDetectionCounter
        GetEventFreezeFrameData: can-be-invoked-concurrently=true, symbol=Dem_GetEventFreezeFrameData
        GetEventExtendedDataRecord: can-be-invoked-concurrently=true, symbol=Dem_GetEventExtendedDataRecord
        GetEventEnableCondition: can-be-invoked-concurrently=true, symbol=Dem_GetEventEnableCondition
        GetDebouncingOfEvent: can-be-invoked-concurrently=true, symbol=Dem_GetDebouncingOfEvent
        DcmClearDTC: can-be-invoked-concurrently=true, symbol=Dem_DcmClearDTC
        DcmGetNextFilteredDTCAndFDC: can-be-invoked-concurrently=true, symbol=Dem_DcmGetNextFilteredDTCAndFDC
        DcmEnableDTCSetting: can-be-invoked-concurrently=true, symbol=Dem_DcmEnableDTCSetting
        DcmGetFreezeFrameDataByDTC: can-be-invoked-concurrently=true, symbol=Dem_DcmGetFreezeFrameDataByDTC
        DcmGetExtendedDataRecordByDTC: can-be-invoked-concurrently=true, symbol=Dem_DcmGetExtendedDataRecordByDTC
        SetOperationCycleState: can-be-invoked-concurrently=true, symbol=Dem_SetOperationCycleState
  swc implementation DemImplementation: programming-language=C, behavior=DemInternalBehavior
